VERSION ""

NS_ :

BS_:

BU_: XXX

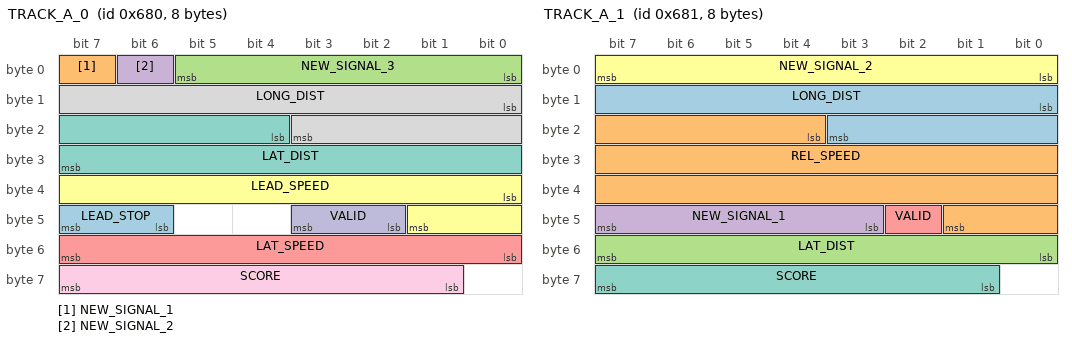
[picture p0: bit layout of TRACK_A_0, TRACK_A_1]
BO_ 1664 TRACK_A_0: 8 XXX
 SG_ LEAD_STOP : 47|2@0+ (1,0) [0|63] "" XXX
 SG_ NEW_SIGNAL_1 : 7|1@1+ (1,0) [0|3] "" XXX
 SG_ NEW_SIGNAL_3 : 0|6@1+ (1,0) [0|15] "" XXX
 SG_ NEW_SIGNAL_2 : 6|1@1+ (1,0) [0|3] "" XXX
 SG_ LAT_SPEED : 48|8@1+ (1,-128) [0|3] "" XXX
 SG_ LEAD_SPEED : 32|10@1+ (0.5,-256) [0|65535] "" XXX
 SG_ LAT_DIST : 20|12@1+ (0.015,-32) [0|7] "m" XXX
 SG_ LONG_DIST : 8|12@1+ (0.05,-1) [0|127] "m" XXX
 SG_ SCORE : 57|7@1+ (1,0) [0|3] "" XXX
 SG_ VALID : 42|2@1+ (1,0) [0|3] "" XXX

BO_ 1665 TRACK_A_1: 8 XXX
 SG_ LONG_DIST : 8|12@1+ (1,0) [0|127] "" XXX
 SG_ REL_SPEED : 20|22@1+ (1,0) [0|65535] "" XXX
 SG_ LAT_DIST : 48|8@1+ (1,-128) [0|3] "" XXX
 SG_ NEW_SIGNAL_1 : 47|5@0+ (1,0) [0|63] "" XXX
 SG_ VALID : 42|1@1+ (1,0) [0|3] "" XXX
 SG_ NEW_SIGNAL_2 : 0|8@1+ (1,0) [0|255] "" XXX
 SG_ SCORE : 57|7@1+ (1,0) [0|3] "" XXX

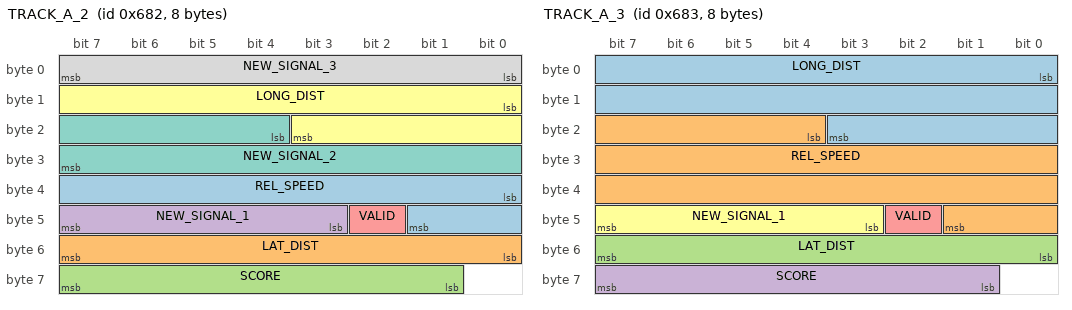
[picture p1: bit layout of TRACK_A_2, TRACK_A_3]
BO_ 1666 TRACK_A_2: 8 XXX
 SG_ REL_SPEED : 32|10@1+ (1,0) [0|65535] "" XXX
 SG_ LAT_DIST : 48|8@1+ (1,-128) [0|3] "" XXX
 SG_ SCORE : 57|7@1+ (1,0) [0|3] "" XXX
 SG_ NEW_SIGNAL_1 : 47|5@0+ (1,0) [0|63] "" XXX
 SG_ VALID : 42|1@1+ (1,0) [0|3] "" XXX
 SG_ LONG_DIST : 8|12@1+ (1,0) [0|127] "" XXX
 SG_ NEW_SIGNAL_2 : 20|12@1+ (1,0) [0|8191] "" XXX
 SG_ NEW_SIGNAL_3 : 0|8@1+ (1,0) [0|63] "" XXX

BO_ 1667 TRACK_A_3: 8 XXX
 SG_ LONG_DIST : 0|20@1+ (1,0) [0|127] "" XXX
 SG_ REL_SPEED : 20|22@1+ (1,0) [0|65535] "" XXX
 SG_ LAT_DIST : 48|8@1+ (1,-128) [0|3] "" XXX
 SG_ SCORE : 57|7@1+ (1,0) [0|3] "" XXX
 SG_ VALID : 42|1@1+ (1,0) [0|3] "" XXX
 SG_ NEW_SIGNAL_1 : 47|5@0+ (1,0) [0|63] "" XXX

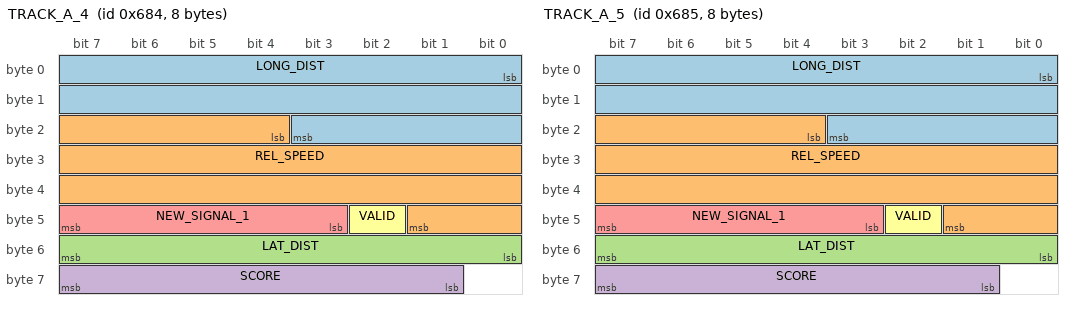
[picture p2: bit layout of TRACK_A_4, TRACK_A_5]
BO_ 1668 TRACK_A_4: 8 XXX
 SG_ LONG_DIST : 0|20@1+ (1,0) [0|127] "" XXX
 SG_ REL_SPEED : 20|22@1+ (1,0) [0|65535] "" XXX
 SG_ LAT_DIST : 48|8@1+ (1,-128) [0|3] "" XXX
 SG_ SCORE : 57|7@1+ (1,0) [0|3] "" XXX
 SG_ NEW_SIGNAL_1 : 47|5@0+ (1,0) [0|63] "" XXX
 SG_ VALID : 42|1@1+ (1,0) [0|3] "" XXX

BO_ 1669 TRACK_A_5: 8 XXX
 SG_ LONG_DIST : 0|20@1+ (1,0) [0|127] "" XXX
 SG_ REL_SPEED : 20|22@1+ (1,0) [0|65535] "" XXX
 SG_ LAT_DIST : 48|8@1+ (1,-128) [0|3] "" XXX
 SG_ SCORE : 57|7@1+ (1,0) [0|3] "" XXX
 SG_ NEW_SIGNAL_1 : 47|5@0+ (1,0) [0|63] "" XXX
 SG_ VALID : 42|1@1+ (1,0) [0|3] "" XXX

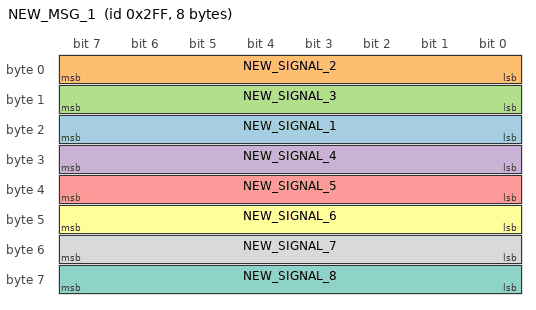
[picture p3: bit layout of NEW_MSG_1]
BO_ 767 NEW_MSG_1: 8 XXX
 SG_ NEW_SIGNAL_1 : 16|8@1+ (1,0) [0|255] "" XXX
 SG_ NEW_SIGNAL_2 : 0|8@1+ (1,0) [0|255] "" XXX
 SG_ NEW_SIGNAL_3 : 8|8@1+ (1,0) [0|255] "" XXX
 SG_ NEW_SIGNAL_4 : 24|8@1+ (1,0) [0|255] "" XXX
 SG_ NEW_SIGNAL_5 : 32|8@1+ (1,0) [0|255] "" XXX
 SG_ NEW_SIGNAL_6 : 40|8@1+ (1,0) [0|255] "" XXX
 SG_ NEW_SIGNAL_8 : 56|8@1+ (1,0) [0|255] "" XXX
 SG_ NEW_SIGNAL_7 : 48|8@1- (1,0) [0|255] "" XXX

CM_ SG_ 1664 LEAD_STOP "lead below 3kph";
CM_ SG_ 1664 SCORE "127 = confident, 87 = low confidence, 0 = no tracking";
